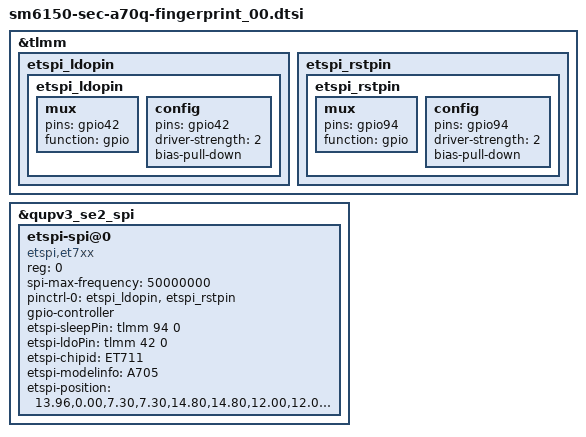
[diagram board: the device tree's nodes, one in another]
/* Copyright (c) 2013-2014, The Linux Foundation. All rights reserved.
 *
 * This program is free software; you can redistribute it and/or modify
 * it under the terms of the GNU General Public License version 2 and
 * only version 2 as published by the Free Software Foundation.
 *
 * This program is distributed in the hope that it will be useful,
 * but WITHOUT ANY WARRANTY; without even the implied warranty of
 * MERCHANTABILITY or FITNESS FOR A PARTICULAR PURPOSE.  See the
 * GNU General Public License for more details.
 */

&tlmm {
	etspi_ldopin {
		etspi_ldopin: etspi_ldopin {
			mux {
				pins = "gpio42";
				function = "gpio";
			};
			config {
				pins = "gpio42";
				driver-strength = <2>;
				bias-pull-down;
			};
		};
	};

	etspi_rstpin {
		etspi_rstpin: etspi_rstpin {
			mux {
				pins = "gpio94";
				function = "gpio";
			};
			config {
				pins = "gpio94";
				driver-strength = <2>;
				bias-pull-down;
			};
		};
	};
};

&qupv3_se2_spi {
	status = "okay";

	etspi-spi@0 {
		compatible = "etspi,et7xx";
		reg = <0>;
		spi-max-frequency = <50000000>;
		pinctrl-names = "default";
		pinctrl-0 = <&etspi_ldopin &etspi_rstpin>;

		gpio-controller;
		#gpio-cells = <2>;

		etspi-sleepPin = <&tlmm 94 0>;
		etspi-ldoPin = <&tlmm 42 0>;
		etspi-chipid = "ET711";
		etspi-modelinfo = "A705";
		etspi-position = "13.96,0.00,7.30,7.30,14.80,14.80,12.00,12.00,5.00";
	};
};
